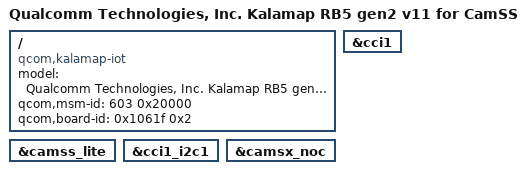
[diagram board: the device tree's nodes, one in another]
/dts-v1/;
/plugin/;
#include "kalamap-rb5-gen2.dtsi"
#include "camss-gen2-lite.dtsi"

/ {
	model = "Qualcomm Technologies, Inc. Kalamap RB5 gen2 v11 for CamSS";
	compatible = "qcom,kalamap-iot", "qcom,kalamap", "qcom,iot";
	qcom,msm-id = <603 0x20000>;
	qcom,board-id = <0x1061f 0x2>;
};

&camss_lite {
	status = "ok";
};

&cci1 {
	status = "ok";
};

&cci1_i2c1 {
	status = "ok";
};

&camsx_noc {
	status = "ok";
};
